VERSION ""

NS_ :

BS_:

BU_: ROS RAPTOR

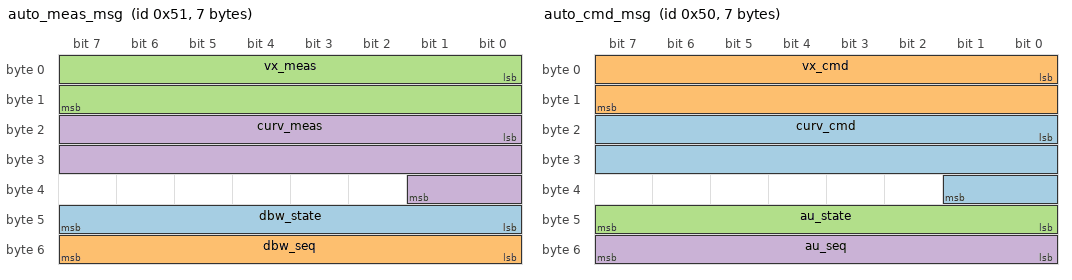
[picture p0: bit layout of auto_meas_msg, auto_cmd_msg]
BO_ 81 auto_meas_msg: 7 ROS
 SG_ dbw_state : 40|8@1+ (1,0) [0|255] "-" Vector__XXX
 SG_ dbw_seq : 48|8@1+ (1,0) [0|255] "-" Vector__XXX
 SG_ vx_meas : 0|16@1- (0.001,0) [-32.768|32.767] "m/s" Vector__XXX
 SG_ curv_meas : 16|18@1- (0.001,0) [-131.072|131.071] "1/m" Vector__XXX

BO_ 80 auto_cmd_msg: 7 ROS
 SG_ curv_cmd : 16|18@1- (0.001,0) [-131.072|131.071] "1/m" Vector__XXX
 SG_ vx_cmd : 0|16@1- (0.001,0) [-32.768|32.767] "m/s" Vector__XXX
 SG_ au_state : 40|8@1+ (1,0) [0|255] "-"  RAPTOR
 SG_ au_seq : 48|8@1+ (1,0) [0|255] "-"  RAPTOR

CM_ BO_ 81 "Measured velocities, Logging and RTK status";
CM_ BO_ 80 "Mobility commands form ROS (Torque and Velocity)";
